# STM32G081 register map
File version: 1.8
CPU: CM0 r0p1, little endian, MPU, no FPU, 2 interrupt priority bits
Registers are 32-bit, read-write, reset 0x0 unless marked. A register's access mark holds for its fields unless they carry their own. Offsets are from the block's base; [hi:lo] are bit positions; {n}, {i} and the like mark numbered series; 'fields as' and 'values as' point back to an identical list.

## RNG — Random number generator
Base 0x40025000
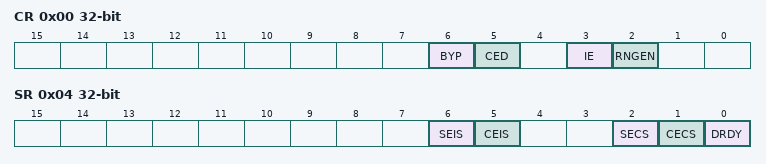
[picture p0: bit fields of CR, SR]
0x00 CR — control register
  [6] BYP — Bypass mode enable
  [5] CED — Clock error detection
  [3] IE — Interrupt enable
  [2] RNGEN — Random number generator enable
0x04 SR access per field — status register
  [6] SEIS rw — Seed error interrupt status
  [5] CEIS rw — Clock error interrupt status
  [2] SECS ro — Seed error current status
  [1] CECS ro — Clock error current status
  [0] DRDY ro — Data ready
0x08 DR ro — data register
  [31:0] RNDATA — Random data

## CRC — Cyclic redundancy check calculation unit
Base 0x40023000
0x00 DR reset 0xFFFFFFFF — Data register
  [31:0] DR — Data register bits
0x00 DR8 8-bit reset 0xFF (alternate view of DR) — Data register - byte sized
  [7:0] DR8 — Data register bits
0x00 DR16 16-bit reset 0xFFFF (alternate view of DR) — Data register - half-word sized
  [15:0] DR16 — Data register bits
0x04 IDR — Independent data register
  [31:0] IDR — General-purpose 32-bit data register bits
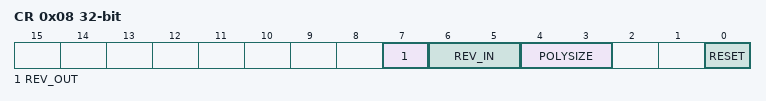
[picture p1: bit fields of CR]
0x08 CR access per field — Control register
  [7] REV_OUT rw — Reverse output data
    0=Normal (Bit order not affected); 1=Reversed (Bit reversed output)
  [6:5] REV_IN rw — Reverse input data
    0=Normal (Bit order not affected); 1=Byte (Bit reversal done by byte); 2=HalfWord (Bit reversal done by half-word); 3=Word (Bit reversal done by word)
  [4:3] POLYSIZE rw — Polynomial size
    0=32-bit polynomial; 1=16-bit polynomial; 2=8-bit polynomial; 3=7-bit polynomial
  [0] RESET wo — RESET bit
    1=Resets the CRC calculation unit and sets the data register to 0xFFFF FFFF
0x10 INIT reset 0xFFFFFFFF — Initial CRC value
  [31:0] INIT — Programmable initial CRC value
0x14 POL reset 0x4C11DB7 — polynomial
  [31:0] POL — Programmable polynomial

## COMP — COMP1
Base 0x40010200
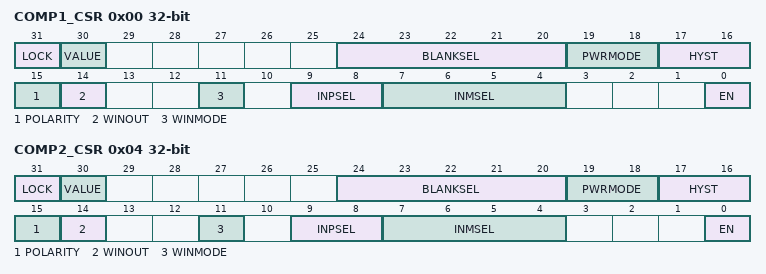
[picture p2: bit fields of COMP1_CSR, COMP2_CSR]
0x00 COMP1_CSR — Comparator 1 control and status register
  [31] LOCK — COMP2_CSR register lock
  [30] VALUE — Comparator 2 output status
  [24:20] BLANKSEL — Comparator 2 blanking source selector
  [19:18] PWRMODE — Comparator 2 power mode selector
  [17:16] HYST — Comparator 2 hysteresis selector
  [15] POLARITY — Comparator 2 polarity selector
  [14] WINOUT — Comparator 2 output selector
  [11] WINMODE — Comparator 2 non-inverting input selector for window mode
  [9:8] INPSEL — Comparator 2 signal selector for non-inverting input
  [7:4] INMSEL — Comparator 2 signal selector for inverting input INM
  [0] EN — COMP channel 1 enable bit
0x04 COMP2_CSR — Comparator 2 control and status register
  fields as COMP1_CSR

## TAMP — Tamper and backup registers
Base 0x4000B000
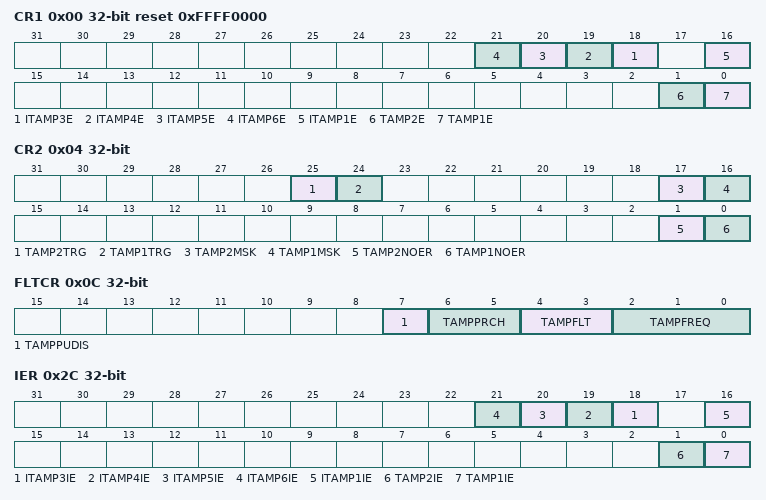
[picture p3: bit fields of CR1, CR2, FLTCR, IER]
0x00 CR1 reset 0xFFFF0000 — control register 1
  [n+15] ITAMP{n}E (n=3..6), [16] ITAMP1E, [1] TAMP2E, [0] TAMP1E
0x04 CR2 — control register 2
  [25] TAMP2TRG, [24] TAMP1TRG, [17] TAMP2MSK, [16] TAMP1MSK, [1] TAMP2NOER, [0] TAMP1NOER
0x0C FLTCR — TAMP filter control register
  [7] TAMPPUDIS, [6:5] TAMPPRCH, [4:3] TAMPFLT, [2:0] TAMPFREQ
0x2C IER — TAMP interrupt enable register
  [n+15] ITAMP{n}IE (n=3..6), [16] ITAMP1IE, [1] TAMP2IE, [0] TAMP1IE
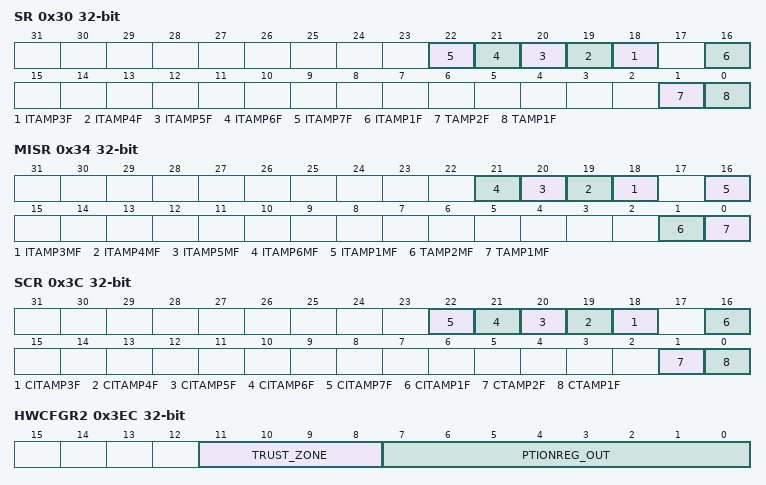
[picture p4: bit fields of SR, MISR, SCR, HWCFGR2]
0x30 SR ro — TAMP status register
  [n+15] ITAMP{n}F (n=3..7), [16] ITAMP1F, [1] TAMP2F, [0] TAMP1F
0x34 MISR ro — TAMP masked interrupt status register
  [n+15] ITAMP{n}MF (n=3..6), [16] ITAMP1MF, [1] TAMP2MF, [0] TAMP1MF
0x3C SCR wo — TAMP status clear register
  [n+15] CITAMP{n}F (n=3..7), [16] CITAMP1F, [1] CTAMP2F, [0] CTAMP1F
{0x100+4i} BKP{i}R (i=0..4) — TAMP backup register
  [31:0] BKP
0x3EC HWCFGR2 ro — TAMP hardware configuration register 2
  [11:8] TRUST_ZONE, [7:0] PTIONREG_OUT
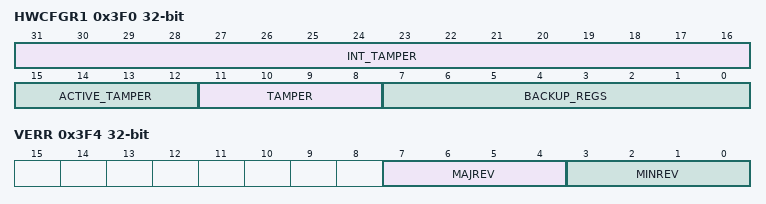
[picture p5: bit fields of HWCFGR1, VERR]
0x3F0 HWCFGR1 ro — TAMP hardware configuration register 1
  [31:16] INT_TAMPER, [15:12] ACTIVE_TAMPER, [11:8] TAMPER, [7:0] BACKUP_REGS
0x3F4 VERR ro — EXTI IP Version register
  [7:4] MAJREV — Major Revision number
  [3:0] MINREV — Minor Revision number
0x3F8 IPIDR ro — EXTI Identification register
  [31:0] IPID — IP Identification
0x3FC SIDR ro — EXTI Size ID register
  [31:0] SID — Size Identification

## TIM6 — Basic timers
Base 0x40001000
Same registers: TIM7 0x40001400
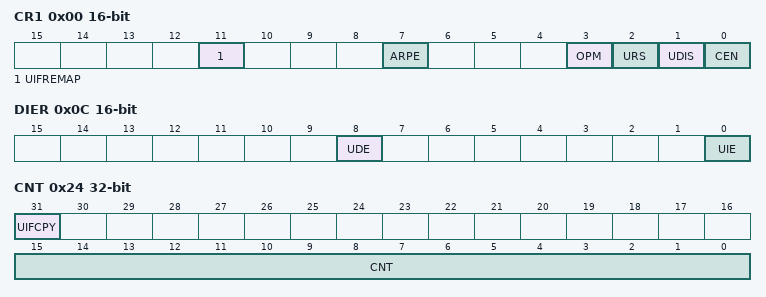
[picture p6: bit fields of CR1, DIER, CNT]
0x00 CR1 16-bit — control register 1
  [11] UIFREMAP — UIF status bit remapping
  [7] ARPE — Auto-reload preload enable
    0=Disabled (TIMx_APRR register is not buffered); 1=Enabled (TIMx_APRR register is buffered)
  [3] OPM — One-pulse mode
    0=Disabled (Counter is not stopped at update event); 1=Enabled (Counter stops counting at the next update event (clearing the CEN bit))
  [2] URS — Update request source
    0=AnyEvent (Any of counter overflow/underflow, setting UG, or update through slave mode, generates an update interrupt or DMA request); 1=CounterOnly (Only counter overflow/underflow generates an update interrupt or DMA request)
  [1] UDIS — Update disable
    0=Enabled (Update event enabled); 1=Disabled (Update event disabled)
  [0] CEN — Counter enable
    0=Disabled (Counter disabled); 1=Enabled (Counter enabled)
0x04 CR2 16-bit — control register 2
  [6:4] MMS — Master mode selection
    0=Reset (Use UG bit from TIMx_EGR register); 1=Enable (Use CNT bit from TIMx_CEN register); 2=Update (Use the update event)
0x0C DIER 16-bit — DMA/Interrupt enable register
  [8] UDE — Update DMA request enable
    0=Disabled (Update DMA request disabled); 1=Enabled (Update DMA request enabled)
  [0] UIE — Update interrupt enable
    0=Disabled (Update interrupt disabled); 1=Enabled (Update interrupt enabled)
0x10 SR 16-bit — status register
  [0] UIF write-0-clears — Update interrupt flag
    on read: 0=NoUpdateOccurred; 1=UpdatePending (Update interrupt pending) | on write: 0=Clear flag
0x14 EGR wo — event generation register
  [0] UG — Update generation
    1=Update (Re-initializes the timer counter and generates an update of the registers.)
0x24 CNT — counter
  [31] UIFCPY — UIF Copy
  [15:0] CNT — Low counter value
0x24 CNT16 16-bit (alternate view of CNT) — 16-bit counter register
  [15:0] CNT — counter value
0x28 PSC 16-bit — prescaler
  [15:0] PSC — Prescaler value
0x2C ARR 16-bit reset 0xFFFF — auto-reload register
  [15:0] ARR — Low Auto-reload value

## VREFBUF — System configuration controller
Base 0x40010030
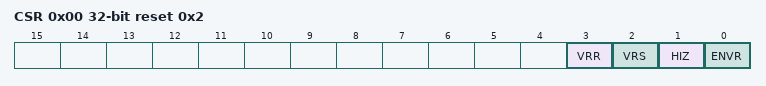
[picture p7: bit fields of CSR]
0x00 CSR access per field reset 0x2 — VREFBUF control and status register
  [3] VRR ro — Voltage reference buffer ready
  [2] VRS rw — Voltage reference scale This bit selects the value generated by the voltage reference buffer.
  [1] HIZ rw — High impedance mode This bit controls the analog switch to connect or not the VREF+ pin. Refer to for the mode descriptions depending on ENVR bit configuration.
  [0] ENVR rw — Voltage reference buffer mode enable This bit is used to enable the voltage reference buffer mode.
0x04 CCR — VREFBUF calibration control register
  [5:0] TRIM — Trimming code These bits are automatically initialized after reset with the trimming value stored in the Flash memory during the production test. Writing into these bits allows the tuning of the internal reference buffer voltage.
